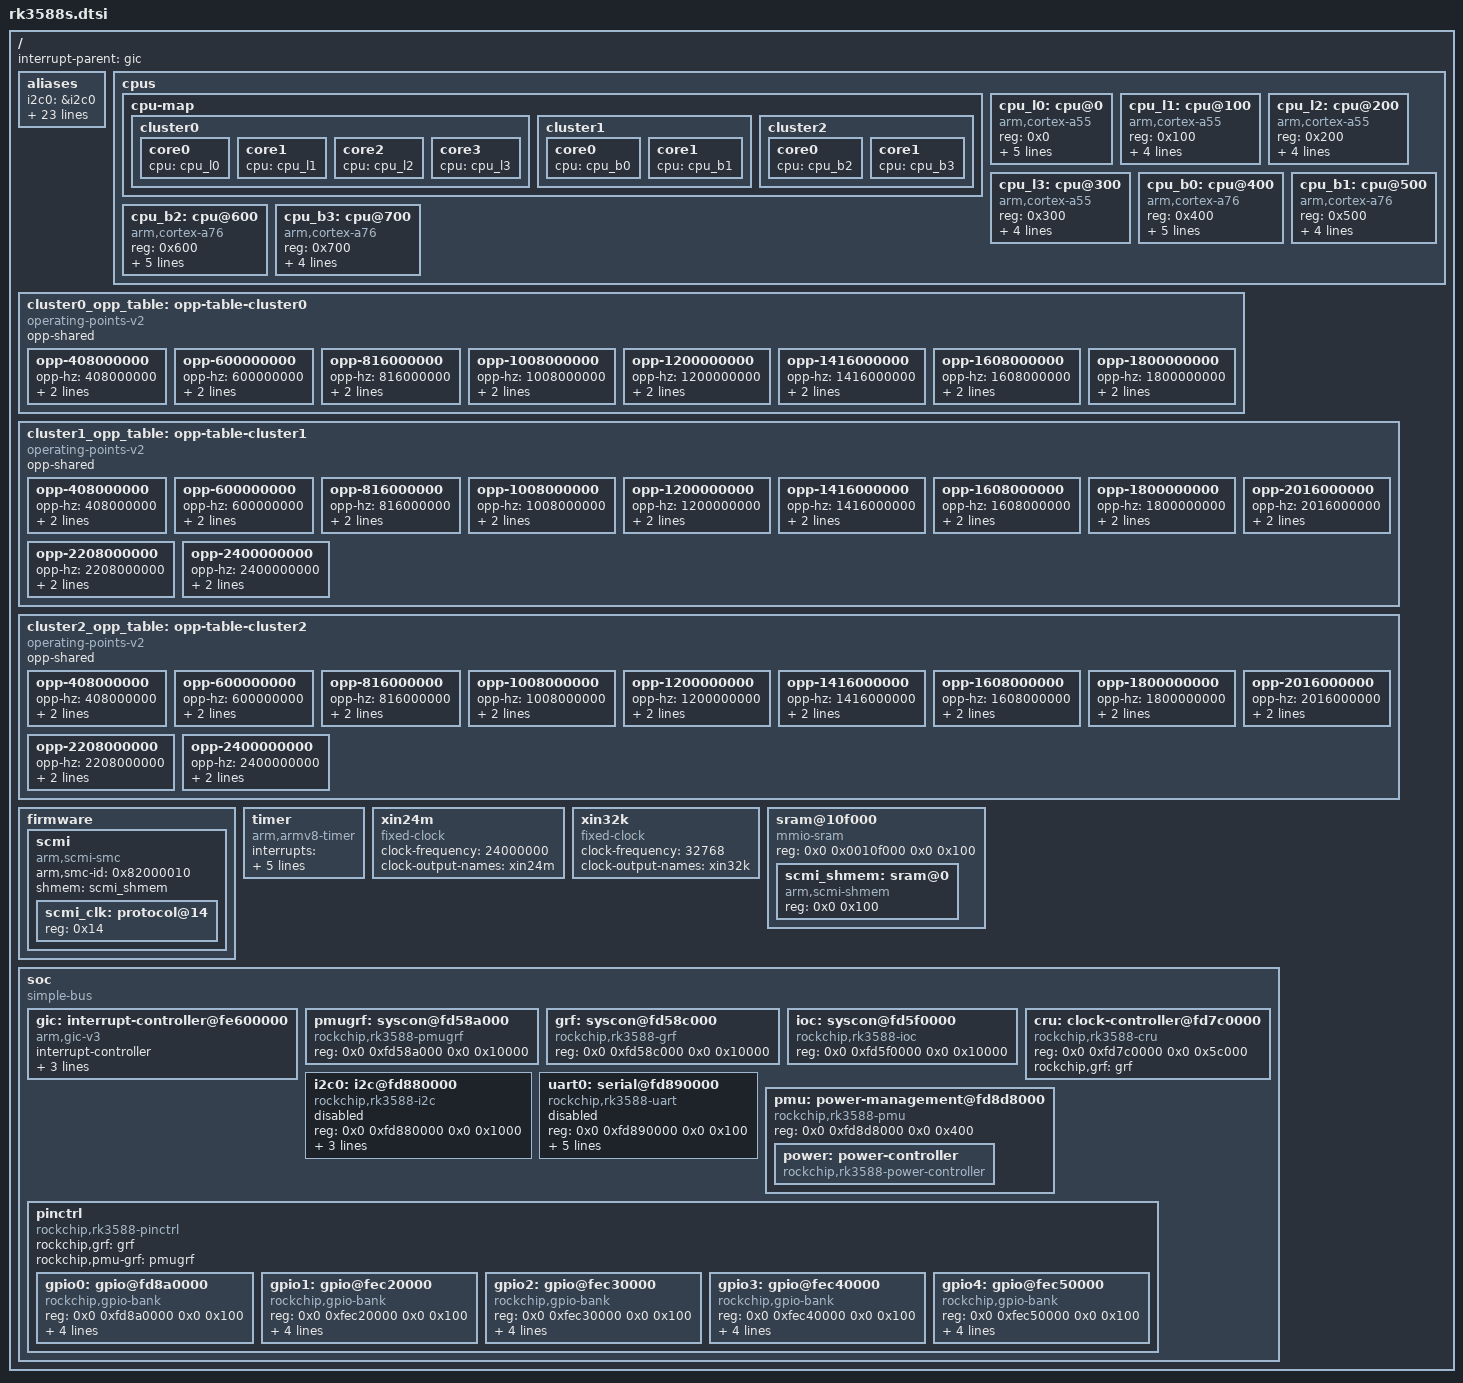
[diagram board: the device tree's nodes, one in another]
// SPDX-License-Identifier: (GPL-2.0+ OR MIT)
/*
 * Copyright (c) 2021 Rockchip Electronics Co., Ltd.
 */

/dts-v1/;

#include <dt-bindings/clock/rk3588-cru.h>
#include <dt-bindings/interrupt-controller/arm-gic.h>
#include <dt-bindings/interrupt-controller/irq.h>
#include <dt-bindings/pinctrl/rockchip.h>
#include <dt-bindings/power/rk3588-power.h>
#include <dt-bindings/reset/rk3588-cru.h>
#include <dt-bindings/thermal/thermal.h>
#include <dt-bindings/gpio/gpio.h>

/ {
	interrupt-parent = <&gic>;
	#address-cells = <2>;
	#size-cells = <2>;

	aliases {
		i2c0 = &i2c0;
		i2c1 = &i2c1;
		i2c2 = &i2c2;
		i2c3 = &i2c3;
		i2c4 = &i2c4;
		i2c5 = &i2c5;
		i2c6 = &i2c6;
		i2c7 = &i2c7;
		i2c8 = &i2c8;
		serial0 = &uart0;
		serial1 = &uart1;
		serial2 = &uart2;
		serial3 = &uart3;
		serial4 = &uart4;
		serial5 = &uart5;
		serial6 = &uart6;
		serial7 = &uart7;
		serial8 = &uart8;
		serial9 = &uart9;
		spi0 = &spi0;
		spi1 = &spi1;
		spi2 = &spi2;
		spi3 = &spi3;
		spi4 = &spi4;
	};

	cpus {
		#address-cells = <1>;
		#size-cells = <0>;

		cpu-map {
			cluster0 {
				core0 {
					cpu = <&cpu_l0>;
				};
				core1 {
					cpu = <&cpu_l1>;
				};
				core2 {
					cpu = <&cpu_l2>;
				};
				core3 {
					cpu = <&cpu_l3>;
				};
			};
			cluster1 {
				core0 {
					cpu = <&cpu_b0>;
				};
				core1 {
					cpu = <&cpu_b1>;
				};
			};
			cluster2 {
				core0 {
					cpu = <&cpu_b2>;
				};
				core1 {
					cpu = <&cpu_b3>;
				};
			};
		};

		cpu_l0: cpu@0 {
			device_type = "cpu";
			compatible = "arm,cortex-a55";
			reg = <0x0>;
			enable-method = "psci";
			capacity-dmips-mhz = <530>;
			clocks = <&scmi_clk SCMI_CLK_CPUL>;
			operating-points-v2 = <&cluster0_opp_table>;
			#cooling-cells = <2>;
			dynamic-power-coefficient = <100>;
		};

		cpu_l1: cpu@100 {
			device_type = "cpu";
			compatible = "arm,cortex-a55";
			reg = <0x100>;
			enable-method = "psci";
			capacity-dmips-mhz = <530>;
			clocks = <&scmi_clk SCMI_CLK_CPUL>;
			operating-points-v2 = <&cluster0_opp_table>;
		};

		cpu_l2: cpu@200 {
			device_type = "cpu";
			compatible = "arm,cortex-a55";
			reg = <0x200>;
			enable-method = "psci";
			capacity-dmips-mhz = <530>;
			clocks = <&scmi_clk SCMI_CLK_CPUL>;
			operating-points-v2 = <&cluster0_opp_table>;
		};

		cpu_l3: cpu@300 {
			device_type = "cpu";
			compatible = "arm,cortex-a55";
			reg = <0x300>;
			enable-method = "psci";
			capacity-dmips-mhz = <530>;
			clocks = <&scmi_clk SCMI_CLK_CPUL>;
			operating-points-v2 = <&cluster0_opp_table>;
		};

		cpu_b0: cpu@400 {
			device_type = "cpu";
			compatible = "arm,cortex-a76";
			reg = <0x400>;
			enable-method = "psci";
			capacity-dmips-mhz = <1024>;
			clocks = <&scmi_clk SCMI_CLK_CPUB01>;
			operating-points-v2 = <&cluster1_opp_table>;
			#cooling-cells = <2>;
			dynamic-power-coefficient = <300>;
		};

		cpu_b1: cpu@500 {
			device_type = "cpu";
			compatible = "arm,cortex-a76";
			reg = <0x500>;
			enable-method = "psci";
			capacity-dmips-mhz = <1024>;
			clocks = <&scmi_clk SCMI_CLK_CPUB01>;
			operating-points-v2 = <&cluster1_opp_table>;
		};

		cpu_b2: cpu@600 {
			device_type = "cpu";
			compatible = "arm,cortex-a76";
			reg = <0x600>;
			enable-method = "psci";
			capacity-dmips-mhz = <1024>;
			clocks = <&scmi_clk SCMI_CLK_CPUB23>;
			operating-points-v2 = <&cluster2_opp_table>;
			#cooling-cells = <2>;
			dynamic-power-coefficient = <300>;
		};

		cpu_b3: cpu@700 {
			device_type = "cpu";
			compatible = "arm,cortex-a76";
			reg = <0x700>;
			enable-method = "psci";
			capacity-dmips-mhz = <1024>;
			clocks = <&scmi_clk SCMI_CLK_CPUB23>;
			operating-points-v2 = <&cluster2_opp_table>;
		};
	};

	cluster0_opp_table: opp-table-cluster0 {
		compatible = "operating-points-v2";
		opp-shared;

		opp-408000000 {
			opp-hz = /bits/ 64 <408000000>;
			opp-microvolt = <675000 675000 950000>;
			clock-latency-ns = <40000>;
		};
		opp-600000000 {
			opp-hz = /bits/ 64 <600000000>;
			opp-microvolt = <675000 675000 950000>;
			clock-latency-ns = <40000>;
		};
		opp-816000000 {
			opp-hz = /bits/ 64 <816000000>;
			opp-microvolt = <675000 675000 950000>;
			clock-latency-ns = <40000>;
		};
		opp-1008000000 {
			opp-hz = /bits/ 64 <1008000000>;
			opp-microvolt = <675000 675000 950000>;
			clock-latency-ns = <40000>;
		};
		opp-1200000000 {
			opp-hz = /bits/ 64 <1200000000>;
			opp-microvolt = <712500 712500 950000>;
			clock-latency-ns = <40000>;
		};
		opp-1416000000 {
			opp-hz = /bits/ 64 <1416000000>;
			opp-microvolt = <762500 762500 950000>;
			clock-latency-ns = <40000>;
		};
		opp-1608000000 {
			opp-hz = /bits/ 64 <1608000000>;
			opp-microvolt = <850000 850000 950000>;
			clock-latency-ns = <40000>;
		};
		opp-1800000000 {
			opp-hz = /bits/ 64 <1800000000>;
			opp-microvolt = <950000 950000 950000>;
			clock-latency-ns = <40000>;
		};
	};

	cluster1_opp_table: opp-table-cluster1 {
		compatible = "operating-points-v2";
		opp-shared;

		opp-408000000 {
			opp-hz = /bits/ 64 <408000000>;
			opp-microvolt = <675000 675000 1000000>;
			clock-latency-ns = <40000>;
		};
		opp-600000000 {
			opp-hz = /bits/ 64 <600000000>;
			opp-microvolt = <675000 675000 1000000>;
			clock-latency-ns = <40000>;
		};
		opp-816000000 {
			opp-hz = /bits/ 64 <816000000>;
			opp-microvolt = <675000 675000 1000000>;
			clock-latency-ns = <40000>;
		};
		opp-1008000000 {
			opp-hz = /bits/ 64 <1008000000>;
			opp-microvolt = <675000 675000 1000000>;
			clock-latency-ns = <40000>;
		};
		opp-1200000000 {
			opp-hz = /bits/ 64 <1200000000>;
			opp-microvolt = <675000 675000 1000000>;
			clock-latency-ns = <40000>;
		};
		opp-1416000000 {
			opp-hz = /bits/ 64 <1416000000>;
			opp-microvolt = <725000 725000 1000000>;
			clock-latency-ns = <40000>;
		};
		opp-1608000000 {
			opp-hz = /bits/ 64 <1608000000>;
			opp-microvolt = <762500 762500 1000000>;
			clock-latency-ns = <40000>;
		};
		opp-1800000000 {
			opp-hz = /bits/ 64 <1800000000>;
			opp-microvolt = <850000 850000 1000000>;
			clock-latency-ns = <40000>;
		};
		opp-2016000000 {
			opp-hz = /bits/ 64 <2016000000>;
			opp-microvolt = <925000 925000 1000000>;
			clock-latency-ns = <40000>;
		};
		opp-2208000000 {
			opp-hz = /bits/ 64 <2208000000>;
			opp-microvolt = <987500 987500 1000000>;
			clock-latency-ns = <40000>;
		};
		opp-2400000000 {
			opp-hz = /bits/ 64 <2400000000>;
			opp-microvolt = <1000000 1000000 1000000>;
			clock-latency-ns = <40000>;
		};
	};

	cluster2_opp_table: opp-table-cluster2 {
		compatible = "operating-points-v2";
		opp-shared;

		opp-408000000 {
			opp-hz = /bits/ 64 <408000000>;
			opp-microvolt = <675000 675000 1000000>;
			clock-latency-ns = <40000>;
		};
		opp-600000000 {
			opp-hz = /bits/ 64 <600000000>;
			opp-microvolt = <675000 675000 1000000>;
			clock-latency-ns = <40000>;
		};
		opp-816000000 {
			opp-hz = /bits/ 64 <816000000>;
			opp-microvolt = <675000 675000 1000000>;
			clock-latency-ns = <40000>;
		};
		opp-1008000000 {
			opp-hz = /bits/ 64 <1008000000>;
			opp-microvolt = <675000 675000 1000000>;
			clock-latency-ns = <40000>;
		};
		opp-1200000000 {
			opp-hz = /bits/ 64 <1200000000>;
			opp-microvolt = <675000 675000 1000000>;
			clock-latency-ns = <40000>;
		};
		opp-1416000000 {
			opp-hz = /bits/ 64 <1416000000>;
			opp-microvolt = <725000 725000 1000000>;
			clock-latency-ns = <40000>;
		};
		opp-1608000000 {
			opp-hz = /bits/ 64 <1608000000>;
			opp-microvolt = <762500 762500 1000000>;
			clock-latency-ns = <40000>;
		};
		opp-1800000000 {
			opp-hz = /bits/ 64 <1800000000>;
			opp-microvolt = <850000 850000 1000000>;
			clock-latency-ns = <40000>;
		};
		opp-2016000000 {
			opp-hz = /bits/ 64 <2016000000>;
			opp-microvolt = <925000 925000 1000000>;
			clock-latency-ns = <40000>;
		};
		opp-2208000000 {
			opp-hz = /bits/ 64 <2208000000>;
			opp-microvolt = <987500 987500 1000000>;
			clock-latency-ns = <40000>;
		};
		opp-2400000000 {
			opp-hz = /bits/ 64 <2400000000>;
			opp-microvolt = <1000000 1000000 1000000>;
			clock-latency-ns = <40000>;
		};
	};

	firmware {
		scmi: scmi {
			compatible = "arm,scmi-smc";
			arm,smc-id = <0x82000010>;
			shmem = <&scmi_shmem>;
			#address-cells = <1>;
			#size-cells = <0>;

			scmi_clk: protocol@14 {
				reg = <0x14>;
				#clock-cells = <1>;
			};
		};
	};

	timer {
		compatible = "arm,armv8-timer";
		interrupts = <GIC_PPI 13 (GIC_CPU_MASK_SIMPLE(8) | IRQ_TYPE_LEVEL_HIGH)>,
			     <GIC_PPI 14 (GIC_CPU_MASK_SIMPLE(8) | IRQ_TYPE_LEVEL_HIGH)>,
			     <GIC_PPI 11 (GIC_CPU_MASK_SIMPLE(8) | IRQ_TYPE_LEVEL_HIGH)>,
			     <GIC_PPI 10 (GIC_CPU_MASK_SIMPLE(8) | IRQ_TYPE_LEVEL_HIGH)>;
		arm,no-tick-in-suspend;
	};

	xin24m: xin24m {
		compatible = "fixed-clock";
		clock-frequency = <24000000>;
		clock-output-names = "xin24m";
		#clock-cells = <0>;
	};

	xin32k: xin32k {
		compatible = "fixed-clock";
		clock-frequency = <32768>;
		clock-output-names = "xin32k";
		#clock-cells = <0>;
	};

	sram@10f000 {
		compatible = "mmio-sram";
		reg = <0x0 0x0010f000 0x0 0x100>;
		#address-cells = <1>;
		#size-cells = <1>;
		ranges = <0 0x0 0x0010f000 0x100>;

		scmi_shmem: sram@0 {
			compatible = "arm,scmi-shmem";
			reg = <0x0 0x100>;
		};
	};

	soc {
		compatible = "simple-bus";
		#address-cells = <2>;
		#size-cells = <2>;
		ranges;

		gic: interrupt-controller@fe600000 {
			compatible = "arm,gic-v3";
			#interrupt-cells = <3>;
			#address-cells = <2>;
			#size-cells = <2>;
			ranges;
			interrupt-controller;
			reg = <0x0 0xfe600000 0 0x10000>, /* GICD */
			      <0x0 0xfe680000 0 0x100000>; /* GICR */
			interrupts = <GIC_PPI 9 IRQ_TYPE_LEVEL_HIGH>;
		};

		pmugrf: syscon@fd58a000 {
			compatible = "rockchip,rk3588-pmugrf", "syscon", "simple-mfd";
			reg = <0x0 0xfd58a000 0x0 0x10000>;
		};

		grf: syscon@fd58c000 {
			compatible = "rockchip,rk3588-grf", "syscon", "simple-mfd";
			reg = <0x0 0xfd58c000 0x0 0x10000>;
		};

		ioc: syscon@fd5f0000 {
			compatible = "rockchip,rk3588-ioc", "syscon";
			reg = <0x0 0xfd5f0000 0x0 0x10000>;
		};

		cru: clock-controller@fd7c0000 {
			compatible = "rockchip,rk3588-cru";
			reg = <0x0 0xfd7c0000 0x0 0x5c000>;
			#clock-cells = <1>;
			#reset-cells = <1>;
			rockchip,grf = <&grf>;
		};

		i2c0: i2c@fd880000 {
			compatible = "rockchip,rk3588-i2c";
			reg = <0x0 0xfd880000 0x0 0x1000>;
			interrupts = <GIC_SPI 317 IRQ_TYPE_LEVEL_HIGH>;
			#address-cells = <1>;
			#size-cells = <0>;
			clocks = <&cru CLK_I2C0>, <&cru PCLK_I2C0>;
			clock-names = "i2c", "pclk";
			pinctrl-names = "default";
			pinctrl-0 = <&i2c0_xfer>;
			status = "disabled";
		};

		uart0: serial@fd890000 {
			compatible = "rockchip,rk3588-uart", "snps,dw-apb-uart";
			reg = <0x0 0xfd890000 0x0 0x100>;
			interrupts = <GIC_SPI 331 IRQ_TYPE_LEVEL_HIGH>;
			clocks = <&cru SCLK_UART0>, <&cru PCLK_UART0>;
			clock-names = "baudclk", "apb_pclk";
			reg-shift = <2>;
			reg-io-width = <4>;
			pinctrl-names = "default";
			pinctrl-0 = <&uart0_xfer>;
			status = "disabled";
		};

		pmu: power-management@fd8d8000 {
			compatible = "rockchip,rk3588-pmu", "syscon", "simple-mfd";
			reg = <0x0 0xfd8d8000 0x0 0x400>;

			power: power-controller {
				compatible = "rockchip,rk3588-power-controller";
				#power-domain-cells = <1>;
				#address-cells = <1>;
				#size-cells = <0>;
			};
		};

		pinctrl: pinctrl {
			compatible = "rockchip,rk3588-pinctrl";
			rockchip,grf = <&grf>;
			rockchip,pmu-grf = <&pmugrf>;
			#address-cells = <2>;
			#size-cells = <2>;
			ranges;

			gpio0: gpio@fd8a0000 {
				compatible = "rockchip,gpio-bank";
				reg = <0x0 0xfd8a0000 0x0 0x100>;
				interrupts = <GIC_SPI 277 IRQ_TYPE_LEVEL_HIGH>;
				clocks = <&cru PCLK_GPIO0>;
				gpio-controller;
				#gpio-cells = <2>;
				interrupt-controller;
				#interrupt-cells = <2>;
			};

			gpio1: gpio@fec20000 {
				compatible = "rockchip,gpio-bank";
				reg = <0x0 0xfec20000 0x0 0x100>;
				interrupts = <GIC_SPI 278 IRQ_TYPE_LEVEL_HIGH>;
				clocks = <&cru PCLK_GPIO1>;
				gpio-controller;
				#gpio-cells = <2>;
				interrupt-controller;
				#interrupt-cells = <2>;
			};

			gpio2: gpio@fec30000 {
				compatible = "rockchip,gpio-bank";
				reg = <0x0 0xfec30000 0x0 0x100>;
				interrupts = <GIC_SPI 279 IRQ_TYPE_LEVEL_HIGH>;
				clocks = <&cru PCLK_GPIO2>;
				gpio-controller;
				#gpio-cells = <2>;
				interrupt-controller;
				#interrupt-cells = <2>;
			};

			gpio3: gpio@fec40000 {
				compatible = "rockchip,gpio-bank";
				reg = <0x0 0xfec40000 0x0 0x100>;
				interrupts = <GIC_SPI 280 IRQ_TYPE_LEVEL_HIGH>;
				clocks = <&cru PCLK_GPIO3>;
				gpio-controller;
				#gpio-cells = <2>;
				interrupt-controller;
				#interrupt-cells = <2>;
			};

			gpio4: gpio@fec50000 {
				compatible = "rockchip,gpio-bank";
				reg = <0x0 0xfec50000 0x0 0x100>;
				interrupts = <GIC_SPI 281 IRQ_TYPE_LEVEL_HIGH>;
				clocks = <&cru PCLK_GPIO4>;
				gpio-controller;
				#gpio-cells = <2>;
				interrupt-controller;
				#interrupt-cells = <2>;
			};
		};
	};

	#include "rk3588s-pinctrl.dtsi"
};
